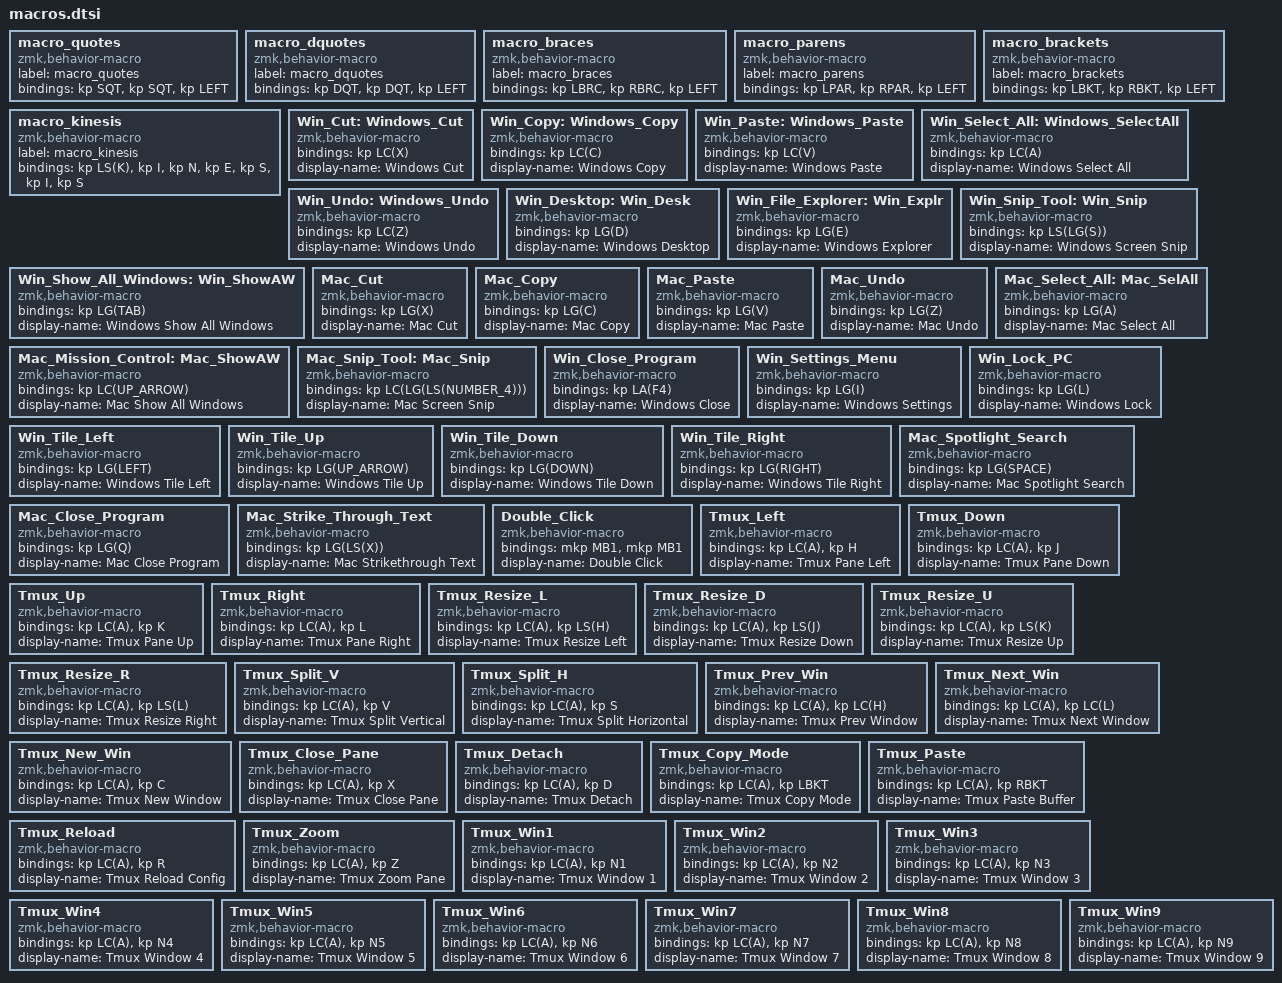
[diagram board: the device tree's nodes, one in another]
  macro_quotes: macro_quotes {
    compatible = "zmk,behavior-macro";
    label = "macro_quotes";
    #binding-cells = <0>;
    bindings = <&kp SQT>, <&kp SQT>, <&kp LEFT>;
  };
  macro_dquotes: macro_dquotes {
    compatible = "zmk,behavior-macro";
    label = "macro_dquotes";
    #binding-cells = <0>;
    bindings = <&kp DQT>, <&kp DQT>, <&kp LEFT>;
  };
  macro_braces: macro_braces {
    compatible = "zmk,behavior-macro";
    label = "macro_braces";
    #binding-cells = <0>;
    bindings = <&kp LBRC>, <&kp RBRC>, <&kp LEFT>;
  };
  macro_parens: macro_parens {
    compatible = "zmk,behavior-macro";
    label = "macro_parens";
    #binding-cells = <0>;
    bindings = <&kp LPAR>, <&kp RPAR>, <&kp LEFT>;
  };
  macro_brackets: macro_brackets {
    compatible = "zmk,behavior-macro";
    label = "macro_brackets";
    #binding-cells = <0>;
    bindings = <&kp LBKT>, <&kp RBKT>, <&kp LEFT>;
  };
  macro_kinesis: macro_kinesis {
    compatible = "zmk,behavior-macro";
    label = "macro_kinesis";
    #binding-cells = <0>;
    bindings = <&kp LS(K)>, <&kp I>, <&kp N>, <&kp E>, <&kp S>, <&kp I>, <&kp S>;
  };
  Win_Cut: Windows_Cut {
    compatible = "zmk,behavior-macro";
    #binding-cells = <0>;
    bindings = <&kp LC(X)>;
    display-name = "Windows Cut";
  };

  Win_Copy: Windows_Copy {
    compatible = "zmk,behavior-macro";
    #binding-cells = <0>;
    bindings = <&kp LC(C)>;
    display-name = "Windows Copy";
  };

  Win_Paste: Windows_Paste {
    compatible = "zmk,behavior-macro";
    #binding-cells = <0>;
    bindings = <&kp LC(V)>;
    display-name = "Windows Paste";
  };

  Win_Select_All: Windows_SelectAll {
      compatible = "zmk,behavior-macro";
      #binding-cells = <0>;
      bindings = <&kp LC(A)>;
      display-name = "Windows Select All";
  };

  Win_Undo: Windows_Undo {
    compatible = "zmk,behavior-macro";
    #binding-cells = <0>;
    bindings = <&kp LC(Z)>;
    display-name = "Windows Undo";
  };

  Win_Desktop: Win_Desk {
    compatible = "zmk,behavior-macro";
    #binding-cells = <0>;
    bindings = <&kp LG(D)>;
    display-name = "Windows Desktop";
  };

  Win_File_Explorer: Win_Explr {
    compatible = "zmk,behavior-macro";
    #binding-cells = <0>;
    bindings = <&kp LG(E)>;
    display-name = "Windows Explorer";
  };

  Win_Snip_Tool: Win_Snip {
    compatible = "zmk,behavior-macro";
    #binding-cells = <0>;
    bindings = <&kp LS(LG(S))>;
    display-name = "Windows Screen Snip";
  };

  Win_Show_All_Windows: Win_ShowAW {
    compatible = "zmk,behavior-macro";
    #binding-cells = <0>;
    bindings = <&kp LG(TAB)>;
    display-name = "Windows Show All Windows";
  };

  Mac_Cut: Mac_Cut {
    compatible = "zmk,behavior-macro";
    #binding-cells = <0>;
    bindings = <&kp LG(X)>;
    display-name = "Mac Cut";
  };

  Mac_Copy: Mac_Copy {
    compatible = "zmk,behavior-macro";
    #binding-cells = <0>;
    bindings = <&kp LG(C)>;
    display-name = "Mac Copy";
  };

  Mac_Paste: Mac_Paste {
    compatible = "zmk,behavior-macro";
    #binding-cells = <0>;
    bindings = <&kp LG(V)>;
    display-name = "Mac Paste";
  };

  Mac_Undo: Mac_Undo {
    compatible = "zmk,behavior-macro";
    #binding-cells = <0>;
    bindings = <&kp LG(Z)>;
    display-name = "Mac Undo";
  };

  Mac_Select_All: Mac_SelAll {
    compatible = "zmk,behavior-macro";
    #binding-cells = <0>;
    bindings = <&kp LG(A)>;
    display-name = "Mac Select All";
  };

  Mac_Mission_Control: Mac_ShowAW {
    compatible = "zmk,behavior-macro";
    #binding-cells = <0>;
    bindings = <&kp LC(UP_ARROW)>;
    display-name = "Mac Show All Windows";
  };

  Mac_Snip_Tool: Mac_Snip {
    compatible = "zmk,behavior-macro";
    #binding-cells = <0>;
    bindings = <&kp LC(LG(LS(NUMBER_4)))>;
    display-name = "Mac Screen Snip";
  };

  Win_Close_Program: Win_Close_Program {
    compatible = "zmk,behavior-macro";
    #binding-cells = <0>;
    bindings = <&kp LA(F4)>;
    display-name = "Windows Close";
  };

  Win_Settings_Menu: Win_Settings_Menu {
    compatible = "zmk,behavior-macro";
    #binding-cells = <0>;
    bindings = <&kp LG(I)>;
    display-name = "Windows Settings";
  };

  Win_Lock_PC: Win_Lock_PC {
    compatible = "zmk,behavior-macro";
    #binding-cells = <0>;
    bindings = <&kp LG(L)>;
    display-name = "Windows Lock";
  };

  Win_Tile_Left: Win_Tile_Left {
    compatible = "zmk,behavior-macro";
    #binding-cells = <0>;
    bindings = <&kp LG(LEFT)>;
    display-name = "Windows Tile Left";
  };

  Win_Tile_Up: Win_Tile_Up {
    compatible = "zmk,behavior-macro";
    #binding-cells = <0>;
    bindings = <&kp LG(UP_ARROW)>;
    display-name = "Windows Tile Up";
  };

  Win_Tile_Down: Win_Tile_Down {
    compatible = "zmk,behavior-macro";
    #binding-cells = <0>;
    bindings = <&kp LG(DOWN)>;
    display-name = "Windows Tile Down";
  };

  Win_Tile_Right: Win_Tile_Right {
    compatible = "zmk,behavior-macro";
    #binding-cells = <0>;
    bindings = <&kp LG(RIGHT)>;
    display-name = "Windows Tile Right";
  };

  Mac_Spotlight_Search: Mac_Spotlight_Search {
    compatible = "zmk,behavior-macro";
    #binding-cells = <0>;
    bindings = <&kp LG(SPACE)>;
    display-name = "Mac Spotlight Search";
  };

  Mac_Close_Program: Mac_Close_Program {
    compatible = "zmk,behavior-macro";
    #binding-cells = <0>;
    bindings = <&kp LG(Q)>;
    display-name = "Mac Close Program";
  };

  Mac_Strike_Through_Text: Mac_Strike_Through_Text {
    compatible = "zmk,behavior-macro";
    #binding-cells = <0>;
    bindings = <&kp LG(LS(X))>;
    display-name = "Mac Strikethrough Text";
  };

  Double_Click: Double_Click {
    compatible = "zmk,behavior-macro";
    #binding-cells = <0>;
    bindings = <&mkp MB1 &mkp MB1>;
    display-name = "Double Click";
  };

  // ──────────────────────────────────────────
  // Tmux macros  (prefix = Ctrl+A)
  // Each macro sends the prefix then the action key.
  // ──────────────────────────────────────────

  // Pane navigation: prefix + h/j/k/l
  Tmux_Left: Tmux_Left {
    compatible = "zmk,behavior-macro";
    #binding-cells = <0>;
    bindings = <&kp LC(A) &kp H>;
    display-name = "Tmux Pane Left";
  };
  Tmux_Down: Tmux_Down {
    compatible = "zmk,behavior-macro";
    #binding-cells = <0>;
    bindings = <&kp LC(A) &kp J>;
    display-name = "Tmux Pane Down";
  };
  Tmux_Up: Tmux_Up {
    compatible = "zmk,behavior-macro";
    #binding-cells = <0>;
    bindings = <&kp LC(A) &kp K>;
    display-name = "Tmux Pane Up";
  };
  Tmux_Right: Tmux_Right {
    compatible = "zmk,behavior-macro";
    #binding-cells = <0>;
    bindings = <&kp LC(A) &kp L>;
    display-name = "Tmux Pane Right";
  };

  // Pane resizing: prefix + H/J/K/L (shifted)
  Tmux_Resize_L: Tmux_Resize_L {
    compatible = "zmk,behavior-macro";
    #binding-cells = <0>;
    bindings = <&kp LC(A) &kp LS(H)>;
    display-name = "Tmux Resize Left";
  };
  Tmux_Resize_D: Tmux_Resize_D {
    compatible = "zmk,behavior-macro";
    #binding-cells = <0>;
    bindings = <&kp LC(A) &kp LS(J)>;
    display-name = "Tmux Resize Down";
  };
  Tmux_Resize_U: Tmux_Resize_U {
    compatible = "zmk,behavior-macro";
    #binding-cells = <0>;
    bindings = <&kp LC(A) &kp LS(K)>;
    display-name = "Tmux Resize Up";
  };
  Tmux_Resize_R: Tmux_Resize_R {
    compatible = "zmk,behavior-macro";
    #binding-cells = <0>;
    bindings = <&kp LC(A) &kp LS(L)>;
    display-name = "Tmux Resize Right";
  };

  // Splits: prefix + v (vertical), prefix + s (horizontal)
  Tmux_Split_V: Tmux_Split_V {
    compatible = "zmk,behavior-macro";
    #binding-cells = <0>;
    bindings = <&kp LC(A) &kp V>;
    display-name = "Tmux Split Vertical";
  };
  Tmux_Split_H: Tmux_Split_H {
    compatible = "zmk,behavior-macro";
    #binding-cells = <0>;
    bindings = <&kp LC(A) &kp S>;
    display-name = "Tmux Split Horizontal";
  };

  // Window navigation: prefix + C-h / C-l
  Tmux_Prev_Win: Tmux_Prev_Win {
    compatible = "zmk,behavior-macro";
    #binding-cells = <0>;
    bindings = <&kp LC(A) &kp LC(H)>;
    display-name = "Tmux Prev Window";
  };
  Tmux_Next_Win: Tmux_Next_Win {
    compatible = "zmk,behavior-macro";
    #binding-cells = <0>;
    bindings = <&kp LC(A) &kp LC(L)>;
    display-name = "Tmux Next Window";
  };

  // Window management
  Tmux_New_Win: Tmux_New_Win {
    compatible = "zmk,behavior-macro";
    #binding-cells = <0>;
    bindings = <&kp LC(A) &kp C>;
    display-name = "Tmux New Window";
  };
  Tmux_Close_Pane: Tmux_Close_Pane {
    compatible = "zmk,behavior-macro";
    #binding-cells = <0>;
    bindings = <&kp LC(A) &kp X>;
    display-name = "Tmux Close Pane";
  };
  Tmux_Detach: Tmux_Detach {
    compatible = "zmk,behavior-macro";
    #binding-cells = <0>;
    bindings = <&kp LC(A) &kp D>;
    display-name = "Tmux Detach";
  };

  // Copy mode & misc
  Tmux_Copy_Mode: Tmux_Copy_Mode {
    compatible = "zmk,behavior-macro";
    #binding-cells = <0>;
    bindings = <&kp LC(A) &kp LBKT>;
    display-name = "Tmux Copy Mode";
  };
  Tmux_Paste: Tmux_Paste {
    compatible = "zmk,behavior-macro";
    #binding-cells = <0>;
    bindings = <&kp LC(A) &kp RBKT>;
    display-name = "Tmux Paste Buffer";
  };
  Tmux_Reload: Tmux_Reload {
    compatible = "zmk,behavior-macro";
    #binding-cells = <0>;
    bindings = <&kp LC(A) &kp R>;
    display-name = "Tmux Reload Config";
  };
  Tmux_Zoom: Tmux_Zoom {
    compatible = "zmk,behavior-macro";
    #binding-cells = <0>;
    bindings = <&kp LC(A) &kp Z>;
    display-name = "Tmux Zoom Pane";
  };

  // Window select by number: prefix + 1-9
  Tmux_Win1: Tmux_Win1 {
    compatible = "zmk,behavior-macro";
    #binding-cells = <0>;
    bindings = <&kp LC(A) &kp N1>;
    display-name = "Tmux Window 1";
  };
  Tmux_Win2: Tmux_Win2 {
    compatible = "zmk,behavior-macro";
    #binding-cells = <0>;
    bindings = <&kp LC(A) &kp N2>;
    display-name = "Tmux Window 2";
  };
  Tmux_Win3: Tmux_Win3 {
    compatible = "zmk,behavior-macro";
    #binding-cells = <0>;
    bindings = <&kp LC(A) &kp N3>;
    display-name = "Tmux Window 3";
  };
  Tmux_Win4: Tmux_Win4 {
    compatible = "zmk,behavior-macro";
    #binding-cells = <0>;
    bindings = <&kp LC(A) &kp N4>;
    display-name = "Tmux Window 4";
  };
  Tmux_Win5: Tmux_Win5 {
    compatible = "zmk,behavior-macro";
    #binding-cells = <0>;
    bindings = <&kp LC(A) &kp N5>;
    display-name = "Tmux Window 5";
  };
  Tmux_Win6: Tmux_Win6 {
    compatible = "zmk,behavior-macro";
    #binding-cells = <0>;
    bindings = <&kp LC(A) &kp N6>;
    display-name = "Tmux Window 6";
  };
  Tmux_Win7: Tmux_Win7 {
    compatible = "zmk,behavior-macro";
    #binding-cells = <0>;
    bindings = <&kp LC(A) &kp N7>;
    display-name = "Tmux Window 7";
  };
  Tmux_Win8: Tmux_Win8 {
    compatible = "zmk,behavior-macro";
    #binding-cells = <0>;
    bindings = <&kp LC(A) &kp N8>;
    display-name = "Tmux Window 8";
  };
  Tmux_Win9: Tmux_Win9 {
    compatible = "zmk,behavior-macro";
    #binding-cells = <0>;
    bindings = <&kp LC(A) &kp N9>;
    display-name = "Tmux Window 9";
  };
